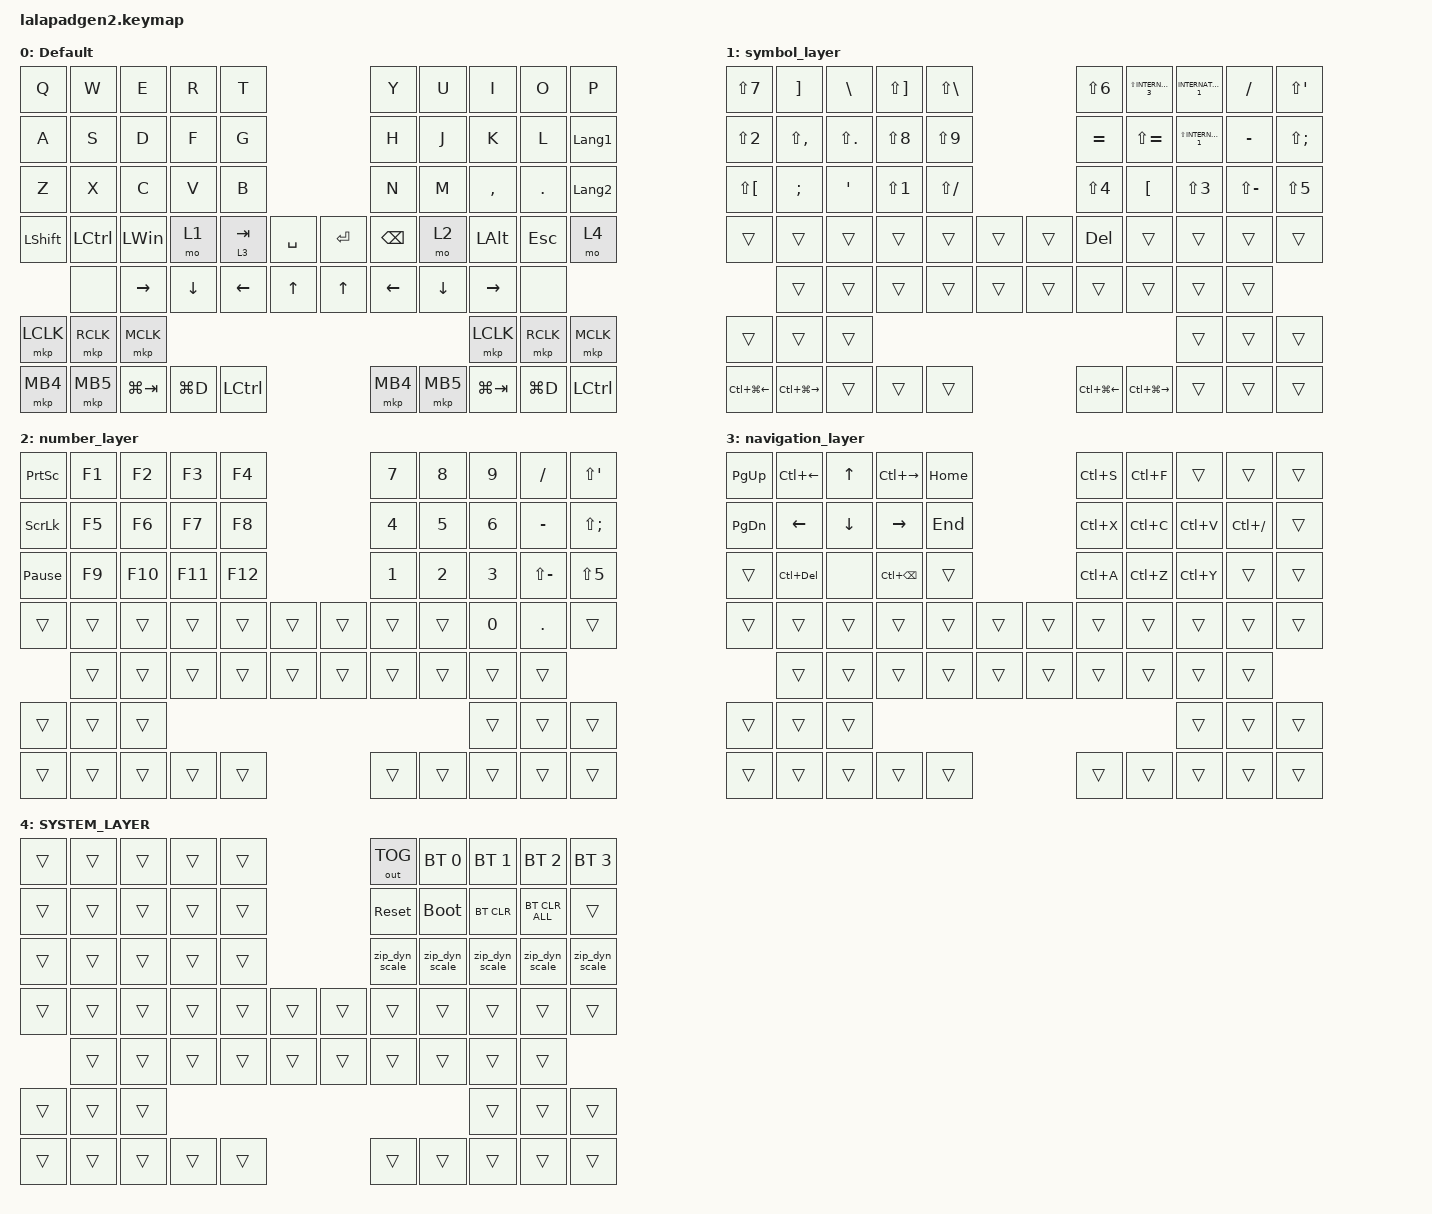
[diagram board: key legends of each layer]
#include <input/processors.dtsi>
#include <dt-bindings/zmk/zip_dynamic_scale.h>
#include <behaviors.dtsi>
#include <dt-bindings/zmk/bt.h>
#include <dt-bindings/zmk/keys.h>
#include <dt-bindings/zmk/outputs.h>
#include <dt-bindings/zmk/pointing.h>

#define DEFAULT_LAYER   0
#define SECONDARY_LAYER 1
#define TERTIARY_LAYER  2
#define SYSTEM_LAYER    3

&mt { quick-tap-ms = <200>; };

&lt { quick-tap-ms = <200>; };

/ {
    behaviors {
        zip_dyn_scale: zip_dyn_scale {
            compatible = "zmk,behavior-zip-dynamic-scale";
            #binding-cells = <2>;
        };

        zip_dyn_scale_set: zip_dyn_scale_set {
            compatible = "zmk,behavior-zip-dynamic-scale-set";
            #binding-cells = <2>;
        };

        mt2: mod_tap2 {
            compatible = "zmk,behavior-hold-tap";
            #binding-cells = <2>;
            flavor = "tap-preferred";
            tapping-term-ms = <200>;
            quick-tap-ms = <200>;
            require-prior-idle-ms = <125>;
            bindings = <&kp>, <&kp>;
        };

        tap_dance_layer_1and2: tap_dance_layer_1and2 {
            compatible = "zmk,behavior-tap-dance";
            label = "td_mo12";
            #binding-cells = <0>;
            bindings = <&mo 1>, <&mo 2>;
        };
    };

    combos {
        compatible = "zmk,combos";

        CONBO_ESC {
            bindings = <&kp ESCAPE>;
            key-positions = <0 1>;
        };

        COMBO_TAB {
            bindings = <&kp TAB>;
            key-positions = <10 11>;
        };
    };

    keymap {
        compatible = "zmk,keymap";

        DEFAULT_LAYER {
            display-name = "Default";
            bindings = <
&kp Q           &kp W      &kp E         &kp R      &kp T                            &kp Y          &kp U     &kp I         &kp O       &kp P
&kp A           &kp S      &kp D         &kp F      &kp G                            &kp H          &kp J     &kp K         &kp L       &kp LANGUAGE_1
&kp Z           &kp X      &kp C         &kp V      &kp B                            &kp N          &kp M     &kp COMMA     &kp PERIOD  &kp LANGUAGE_2
&kp LEFT_SHIFT  &kp LCTRL  &kp LEFT_WIN  &mo 1      &lt 3 TAB  &kp SPACE  &kp ENTER  &kp BACKSPACE  &mo 2     &kp LEFT_ALT  &kp ESCAPE  &mo 4
                &none      &kp RIGHT     &kp DOWN   &kp LEFT   &kp UP     &kp UP     &kp LEFT       &kp DOWN  &kp RIGHT     &none
&mkp LCLK       &mkp RCLK  &mkp MCLK                                                                          &mkp LCLK     &mkp RCLK   &mkp MCLK
&mkp MB4        &mkp MB5   &kp LG(TAB)   &kp LG(D)  &kp LCTRL                        &mkp MB4       &mkp MB5  &kp LG(TAB)   &kp LG(D)   &kp LCTRL
            >;
        };

        SYMBOL_LAYER {
            display-name = "symbol_layer";
            bindings = <
&kp LS(N7)        &kp RBKT           &kp BSLH     &kp LS(RBKT)  &kp LS(BSLH)                  &kp LS(N6)        &kp LS(INTERNATIONAL_3)  &kp INTERNATIONAL_1      &kp FSLH       &kp LS(SQT)
&kp LS(N2)        &kp LS(COMMA)      &kp LS(DOT)  &kp LS(N8)    &kp LS(N9)                    &kp EQUAL         &kp LS(EQUAL)            &kp LS(INTERNATIONAL_1)  &kp MINUS      &kp LS(SEMI)
&kp LS(LBKT)      &kp SEMI           &kp SQT      &kp LS(N1)    &kp LS(FSLH)                  &kp LS(N4)        &kp LBKT                 &kp LS(N3)               &kp LS(MINUS)  &kp LS(N5)
&trans            &trans             &trans       &trans        &trans        &trans  &trans  &kp DEL           &trans                   &trans                   &trans         &trans
                  &trans             &trans       &trans        &trans        &trans  &trans  &trans            &trans                   &trans                   &trans
&trans            &trans             &trans                                                                                              &trans                   &trans         &trans
&kp LC(LG(LEFT))  &kp LC(LG(RIGHT))  &trans       &trans        &trans                        &kp LC(LG(LEFT))  &kp LC(LG(RIGHT))        &trans                   &trans         &trans
            >;
        };

        NUMBER_LAYER {
            display-name = "number_layer";
            bindings = <
&kp PRINTSCREEN  &kp F1  &kp F2   &kp F3   &kp F4                   &kp N7        &kp N8        &kp N9        &kp FSLH       &kp LS(SQT)
&kp SLCK         &kp F5  &kp F6   &kp F7   &kp F8                   &kp NUMBER_4  &kp N5        &kp NUMBER_6  &kp MINUS      &kp LS(SEMI)
&kp PAUSE_BREAK  &kp F9  &kp F10  &kp F11  &kp F12                  &kp NUMBER_1  &kp NUMBER_2  &kp NUMBER_3  &kp LS(MINUS)  &kp LS(N5)
&trans           &trans  &trans   &trans   &trans   &trans  &trans  &trans        &trans        &kp N0        &kp DOT        &trans
                 &trans  &trans   &trans   &trans   &trans  &trans  &trans        &trans        &trans        &trans
&trans           &trans  &trans                                                                 &trans        &trans         &trans
&trans           &trans  &trans   &trans   &trans                   &trans        &trans        &trans        &trans         &trans
            >;
        };

        NAVIGATION_LAYER {
            display-name = "navigation_layer";
            bindings = <
&kp PG_UP      &kp LC(LEFT)  &kp UP    &kp LC(RIGHT)      &kp HOME                  &kp LC(S)  &kp LC(F)  &trans     &trans        &trans
&kp PAGE_DOWN  &kp LEFT      &kp DOWN  &kp RIGHT          &kp END                   &kp LC(X)  &kp LC(C)  &kp LC(V)  &kp LC(FSLH)  &trans
&trans         &kp LC(DEL)   &none     &kp LC(BACKSPACE)  &trans                    &kp LC(A)  &kp LC(Z)  &kp LC(Y)  &trans        &trans
&trans         &trans        &trans    &trans             &trans    &trans  &trans  &trans     &trans     &trans     &trans        &trans
               &trans        &trans    &trans             &trans    &trans  &trans  &trans     &trans     &trans     &trans
&trans         &trans        &trans                                                                       &trans     &trans        &trans
&trans         &trans        &trans    &trans             &trans                    &trans     &trans     &trans     &trans        &trans
            >;
        };

        SYSTEM_LAYER {
            bindings = <
&trans  &trans  &trans  &trans  &trans                  &out OUT_TOG    &bt BT_SEL 0    &bt BT_SEL 1    &bt BT_SEL 2    &bt BT_SEL 3
&trans  &trans  &trans  &trans  &trans                  &sys_reset      &bootloader     &bt BT_CLR      &bt BT_CLR_ALL  &trans
&trans  &trans  &trans  &trans  &trans                  &zip_dyn_scale  &zip_dyn_scale  &zip_dyn_scale  &zip_dyn_scale  &zip_dyn_scale
&trans  &trans  &trans  &trans  &trans  &trans  &trans  &trans          &trans          &trans          &trans          &trans
        &trans  &trans  &trans  &trans  &trans  &trans  &trans          &trans          &trans          &trans
&trans  &trans  &trans                                                                  &trans          &trans          &trans
&trans  &trans  &trans  &trans  &trans                  &trans          &trans          &trans          &trans          &trans
            >;
        };
    };

    conditional_layers {
        compatible = "zmk,conditional-layers";

        Cond_Syslayer {
            if-layers = <1 2>;
            then-layer = <4>;
        };
    };
};
